# APM32F00x register map
File version: 1.0
APM32F00x SVD APM32F00x ARM 32-bit Cortex-M0 Microcontroller based device
CPU: CM0+ r0p1, little endian, no MPU, no FPU, 4 interrupt priority bits
Registers are 32-bit, read-write, reset 0x0 unless marked. A register's access mark holds for its fields unless they carry their own. Offsets are from the block's base; lines under a group give offsets from that group; [hi:lo] are bit positions; {n}, {i} and the like mark numbered series; 'fields as' and 'values as' point back to an identical list; <NAME> marks a mode.

## Memory map
0x00020400 OB size 0x400 — Option Bytes Registers
0x40000000 GPIOA size 0x400 — General purpose I/O
0x40000400 GPIOB size 0x400
0x40000800 GPIOC size 0x400
0x40000C00 GPIOD size 0x400
0x40001000 TMR1A size 0x400
0x40001400 USART2 size 0x400 — Universal asynchronous receiver transmitter
0x40001800 EINT size 0x400 — External interrupt control
0x40001C00 WWDT size 0x400 — Window Watchdog
0x40002000 IWDT size 0x400 — Independent Watchdog
0x40002400 WUPT size 0x400 — Auto wake up
0x40002800 BUZZER size 0x400 — Beeper
0x40002C00 SPI size 0x400 — Serial peripheral interface
0x40003000 I2C size 0x400 — Inter-integrated circuit interface
0x40003400 USART1 size 0x400 — Universal asynchronous receiver transmitter
0x40003800 TMR1 size 0x400 — 16-bit timer with complementary PWM outputs
0x40003C00 TMR2 size 0x400 — 16-bit timer
0x40004000 TMR4 size 0x400 — 8-bit timer
0x40004400 ADC size 0x400 — Analog to digital converter
0x40004800 USART3 size 0x400 — Universal asynchronous receiver transmitter
0x40010000 RCM size 0x400 — Reset and Clock Management
0x40011000 FMC size 0x400 — Flash Interface

## Interrupts
1 WUPT — Auto wake up from halt interrupt
2 RCM — Clock controller interrupt
3 EINTA (GPIOA) — Popt A external interrupts
4 EINTB (GPIOB) — Popt B external interrupts
5 EINTC (GPIOC) — Popt C external interrupts
6 EINTD (GPIOD) — Popt D external interrupts
10 SPI — SPI Interrupt
11 TMR1_UT (TMR1) — TIM1 update/overflow/underflow/trigger/break interrupt
12 TMR1_CC (TMR1) — TIM1 capture/compare interrupt
13 TMR2_UO (TMR2) — TIM2 update /overflow interrupt
14 TMR2_CC (TMR2) — TIM2 capture/compare interrupt
17 USART1_TX (USART1) — USART1 TX interrupt
18 USART1_RX (USART1) — USART1 RX interrupt
19 IIC (I2C) — I2C Interrupt
22 ADC — ADC global interrupt
23 TMR4 — TIM4 update /overflow interrupt
24 FLASH (FMC) — Flash interrupt
25 USART3_TX (USART3) — USART3 TX interrupt
26 USART3_RX (USART3) — USART3 RX interrupt
27 USART2_TX (USART2) — USART2 TX interrupt
28 USART2_RX (USART2) — USART2 RX interrupt
29 TMR1A_UT (TMR1A) — TIM1 update/overflow/underflow/trigger/break interrupt
30 TMR1A_CC (TMR1A) — TIM1 capture/compare interrupt

## GPIOA — General purpose I/O
Base 0x40000000
Same registers: GPIOB 0x40000400, GPIOC 0x40000800, GPIOD 0x40000C00
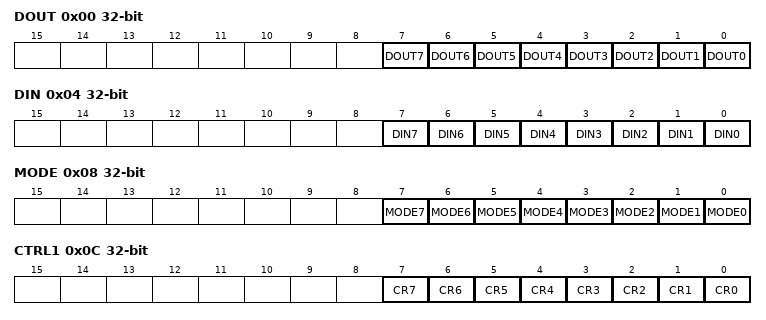
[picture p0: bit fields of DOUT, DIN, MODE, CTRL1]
0x00 DOUT — Port output data register (GPIOn_DOUT)
  [n] DOUT{n} (n=0..7) — Port output data {n}
0x04 DIN ro — Port input data register (GPIOn_DIN)
  [n] DIN{n} (n=0..7) — Port input data {n}
0x08 MODE — Port data data register (GPIOnMODE)
  [n] MODE{n} (n=0..7) — ouput mode {n}
0x0C CTRL1 — Port configuration register 1 (GPIOn_CTRL1)
  [n] CR{n} (n=0..7) — Port function configuration
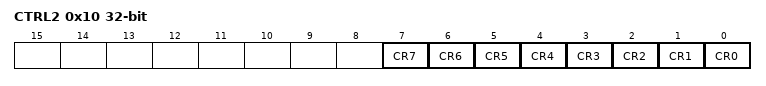
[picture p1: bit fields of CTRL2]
0x10 CTRL2 — Port configuration register 2 (GPIOn_CTRL2)
  [n] CR{n} (n=0..7) — Port mode configuration
0x100 GPIO_JTAGDIS — JTAG IO configuration register (GPIOn_GPIO_JTAGDIS)
  [0] JTAGDIS — JTAG IO configuration

## RCM — Reset and Clock Management
Base 0x40010000
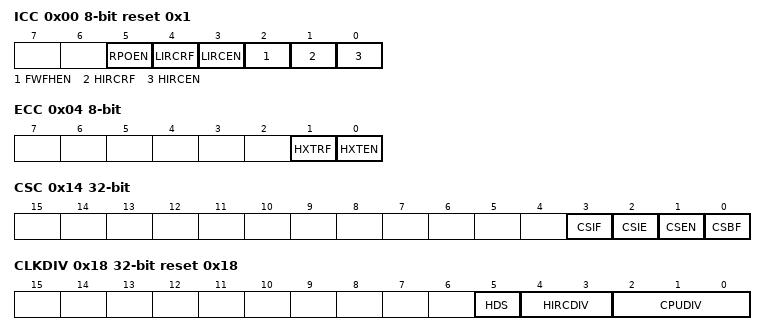
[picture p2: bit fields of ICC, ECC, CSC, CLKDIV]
0x00 ICC 8-bit access per field reset 0x1 — Internal Clocks Control Register
  [5] RPOEN rw — Slow Wake-up from Active Halt/Halt modes
  [4] LIRCRF ro — Low speed internal oscillator ready
  [3] LIRCEN rw — Low speed internal RC oscillator enable
  [2] FWFHEN rw — Fast Wake-up from Active Halt/Halt mode
  [1] HIRCRF ro — High speed internal RC oscillator ready
  [0] HIRCEN rw — High speed internal RC oscillator enable
0x04 ECC 8-bit access per field — External Interrupt Control Register for PORTE and TLI
  [1] HXTRF ro — High speed external crystal oscillator ready
  [0] HXTEN rw — High speed external crystal oscillator enable
0x0C MCS ro reset 0xE1 — Clock Master Status Register
  [7:0] MCS — Clock master status bits
0x10 MCC reset 0xE1 — Clock Master Switch Register
  [7:0] MCC — Clock master selection bits
0x14 CSC — Switch Control Register
  [3] CSIF — Clock switch interrupt flag
  [2] CSIE — Clock switch interrupt enable
  [1] CSEN — Switch start/stop
  [0] CSBF — Switch busy flag
0x18 CLKDIV reset 0x18 — Clock Divider Register
  [5] HDS
  [4:3] HIRCDIV — CPU clock prescaler
  [2:0] CPUDIV — High speed internal clock prescaler
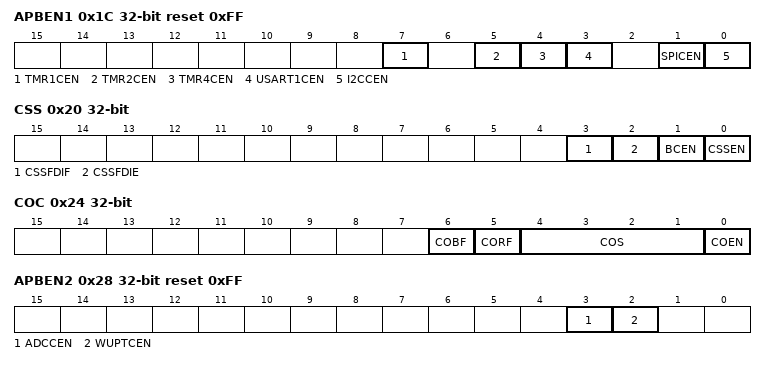
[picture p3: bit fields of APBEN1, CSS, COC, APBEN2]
0x1C APBEN1 reset 0xFF — APB peripheral clock enable register1
  [7] TMR1CEN — Timer 1 clock enable
  [5] TMR2CEN — Timer 2 clock enable
  [4] TMR4CEN — Timer 4 clock enable
  [3] USART1CEN — USART1 clock enabl
  [1] SPICEN — SPI clock enable
  [0] I2CCEN — I2C clock enable
0x20 CSS access per field — Clock security system register
  [3] CSSFDIF rw — Clock security system detection
  [2] CSSFDIE rw — Clock security system detection interrupt enable
  [1] BCEN ro — Auxiliary oscillator connected to master clock
  [0] CSSEN rw — Clock security system enable
0x24 COC access per field — clock output control register
  [6] COBF ro — Configurable clock output busy
  [5] CORF ro — Configurable clock output ready
  [4:1] COS rw — Configurable clock output selection
  [0] COEN rw — Configurable clock output enable
0x28 APBEN2 reset 0xFF — APB peripheral clock enable register2
  [3] ADCCEN — ADC clock enable
  [2] WUPTCEN — AWU clock enable
0x30 HIRCTRIM — HIRC clock calibration trimming register
  [3:0] TRIM — High speed internal oscillator trimmer
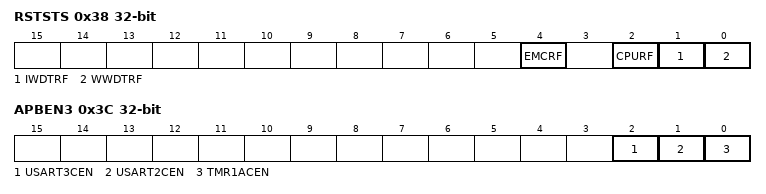
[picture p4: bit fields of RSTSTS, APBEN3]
0x38 RSTSTS — Reset status register
  [4] EMCRF — EMC reset flag bit mask
  [2] CPURF — CPU software reset flag bit mask
  [1] IWDTRF — IWDG reset flag bit mask
  [0] WWDTRF — WWDG reset flag bit mask
0x3C APBEN3 — APB peripheral clock enable register3
  [2] USART3CEN — USART3 clock enable
  [1] USART2CEN — USART2 clock enable
  [0] TMR1ACEN — TMR1 clock enable
